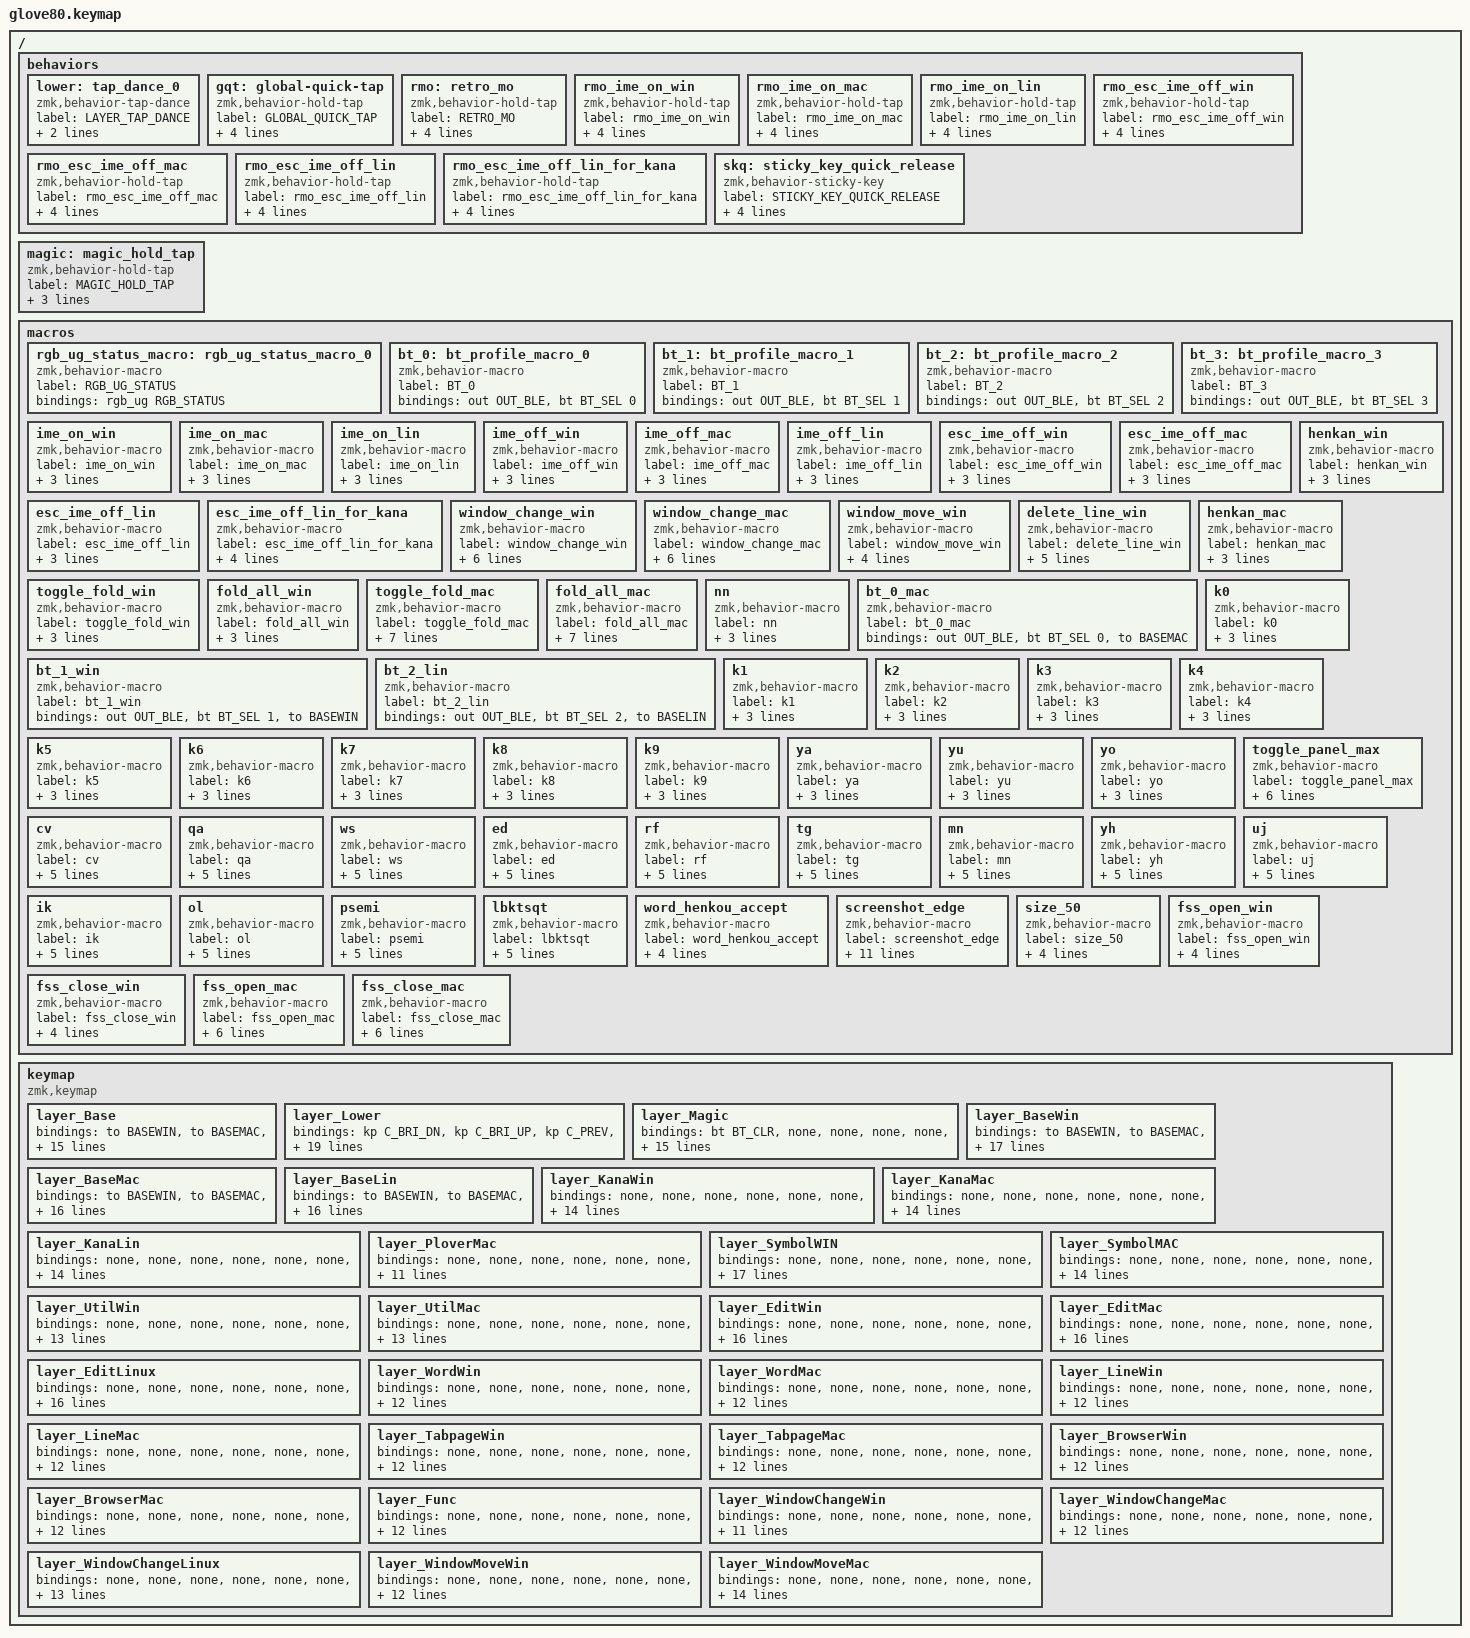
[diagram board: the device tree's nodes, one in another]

/*
 * Copyright (c) 2020 The ZMK Contributors
 * Copyright (c) 2022 Innaworks Development Limited, trading as MoErgo
 *
 * SPDX-License-Identifier: MIT
 */


/* THIS FILE WAS GENERATED BY GLOVE80 LAYOUT EDITOR
 *
 * This file was generated automatically. You may or may not want to
 * edit it directly.
 */

#include <behaviors.dtsi>
/* Include all behaviour includes needed by system behaviors/macros */
#include <dt-bindings/zmk/outputs.h>

/* Include behaviour includes needed by key binds - automatically generated */
#include <dt-bindings/zmk/keys.h>
#include <dt-bindings/zmk/bt.h>
#include <dt-bindings/zmk/rgb.h>
#include <dt-bindings/zmk/outputs.h>


// レイヤーはmaxで32個の模様。それ以上にするとビルドはできるが、動作しない。
#define ORIGINAL_BASE 0
#define ORIGINAL_LOWER 1
#define ORIGINAL_MAGIC 2
#define BASEWIN 3
#define BASEMAC 4
#define BASELIN 5
#define KANAWIN 6
#define KANAMAC 7
#define KANALIN 8
#define PLOVERMAC 9
#define SYMBOLWIN 10
#define SYMBOLMAC 11
#define UTILWIN  12
#define UTILMAC 13
#define EDITWIN 14
#define EDITMAC 15
#define EDITLIN 16
#define WORDWIN 17
#define WORDMAC 18
#define LINEWIN 19
#define LINEMAC 20
#define TABPAGEWIN 21
#define TABPAGEMAC 22
#define BROWSERWIN 23
#define BROWSERMAC 24
#define FUNC 25
#define WINDOWCHANGEWIN 26
#define WINDOWCHANGEMAC 27
#define WINDOWCHANGELIN 28
#define WINDOWMOVEWIN 29
#define WINDOWMOVEMAC 30


/ {
    /* Glove80 system behavior & macros */
    behaviors {
        // For the "layer" key, it'd nice to be able to use it as either a shift or a toggle.
        // Configure it as a tap dance, so the first tap (or hold) is a &mo and the second tap is a &to
        lower: tap_dance_0 {
            compatible = "zmk,behavior-tap-dance";
            label = "LAYER_TAP_DANCE";
            #binding-cells = <0>;
            tapping-term-ms = <200>;
            bindings = <&mo ORIGINAL_LOWER>, <&to ORIGINAL_LOWER>;
        };
        gqt: global-quick-tap {
            compatible = "zmk,behavior-hold-tap";
            label = "GLOBAL_QUICK_TAP";
            #binding-cells = <2>;
            flavor = "hold-preferred";
            tapping-term-ms = <200>;
            retro-tap;
            bindings = <&kp>, <&kp>;
        };
        rmo: retro_mo {
            compatible = "zmk,behavior-hold-tap";
            label = "RETRO_MO";
            #binding-cells = <2>;
            flavor = "hold-preferred";
            tapping-term-ms = <200>;
            retro-tap;
            bindings = <&mo>, <&kp>;
        };
        rmo_ime_on_win: rmo_ime_on_win {
            compatible = "zmk,behavior-hold-tap";
            label = "rmo_ime_on_win";
            #binding-cells = <2>;
            flavor = "hold-preferred";
            tapping-term-ms = <0>;
            retro-tap;
            bindings = <&mo>, <&ime_on_win>;
        };
        rmo_ime_on_mac: rmo_ime_on_mac {
            compatible = "zmk,behavior-hold-tap";
            label = "rmo_ime_on_mac";
            #binding-cells = <2>;
            flavor = "hold-preferred";
            tapping-term-ms = <0>;
            retro-tap;
            bindings = <&mo>, <&ime_on_mac>;
        };
        rmo_ime_on_lin: rmo_ime_on_lin {
            compatible = "zmk,behavior-hold-tap";
            label = "rmo_ime_on_lin";
            #binding-cells = <2>;
            flavor = "hold-preferred";
            tapping-term-ms = <0>;
            retro-tap;
            bindings = <&mo>, <&ime_on_lin>;
        };
        rmo_esc_ime_off_win: rmo_esc_ime_off_win {
            compatible = "zmk,behavior-hold-tap";
            label = "rmo_esc_ime_off_win";
            #binding-cells = <2>;
            flavor = "hold-preferred";
            tapping-term-ms = <0>;
            retro-tap;
            bindings = <&mo>, <&esc_ime_off_win>;
        };
        rmo_esc_ime_off_mac: rmo_esc_ime_off_mac {
            compatible = "zmk,behavior-hold-tap";
            label = "rmo_esc_ime_off_mac";
            #binding-cells = <2>;
            flavor = "hold-preferred";
            tapping-term-ms = <0>;
            retro-tap;
            bindings = <&mo>, <&esc_ime_off_mac>;
        };
        rmo_esc_ime_off_lin: rmo_esc_ime_off_lin {
            compatible = "zmk,behavior-hold-tap";
            label = "rmo_esc_ime_off_lin";
            #binding-cells = <2>;
            flavor = "hold-preferred";
            tapping-term-ms = <0>;
            retro-tap;
            bindings = <&mo>, <&esc_ime_off_lin>;
        };
        rmo_esc_ime_off_lin_for_kana: rmo_esc_ime_off_lin_for_kana {
            compatible = "zmk,behavior-hold-tap";
            label = "rmo_esc_ime_off_lin_for_kana";
            #binding-cells = <2>;
            flavor = "hold-preferred";
            tapping-term-ms = <0>;
            retro-tap;
            bindings = <&mo>, <&esc_ime_off_lin_for_kana>;
        };
        skq: sticky_key_quick_release {
            compatible = "zmk,behavior-sticky-key";
            label = "STICKY_KEY_QUICK_RELEASE";
            #binding-cells = <1>;
            bindings = <&kp>;
            release-after-ms = <1000>;
            quick-release;
            ignore-modifiers;
        };
    };

    magic: magic_hold_tap {
        compatible = "zmk,behavior-hold-tap";
        label = "MAGIC_HOLD_TAP";
        #binding-cells = <2>;
        flavor = "tap-preferred";
        tapping-term-ms = <200>;
        bindings = <&mo>, <&rgb_ug_status_macro>;
    };

    macros {
        rgb_ug_status_macro: rgb_ug_status_macro_0 {
            label = "RGB_UG_STATUS";
            compatible = "zmk,behavior-macro";
            #binding-cells = <0>;
            bindings
                = <&rgb_ug RGB_STATUS>;
        };

        bt_0: bt_profile_macro_0 {
            label = "BT_0";
            compatible = "zmk,behavior-macro";
            #binding-cells = <0>;
            bindings
                = <&out OUT_BLE>,
                  <&bt BT_SEL 0>;
        };

        bt_1: bt_profile_macro_1 {
            label = "BT_1";
            compatible = "zmk,behavior-macro";
            #binding-cells = <0>;
            bindings
                = <&out OUT_BLE>,
                  <&bt BT_SEL 1>;
        };

        bt_2: bt_profile_macro_2 {
            label = "BT_2";
            compatible = "zmk,behavior-macro";
            #binding-cells = <0>;
            bindings
                = <&out OUT_BLE>,
                  <&bt BT_SEL 2>;
        };

        bt_3: bt_profile_macro_3 {
            label = "BT_3";
            compatible = "zmk,behavior-macro";
            #binding-cells = <0>;
            bindings
                = <&out OUT_BLE>,
                  <&bt BT_SEL 3>;
        };

        ime_on_win: ime_on_win {
            label = "ime_on_win";
            compatible = "zmk,behavior-macro";
            #binding-cells = <0>;
            wait-ms = <0>;
            tap-ms = <0>;
            bindings
                = <&kp LANG1>
                , <&to KANAWIN>
                ;
        };
        ime_on_mac: ime_on_mac {
            label = "ime_on_mac";
            compatible = "zmk,behavior-macro";
            #binding-cells = <0>;
            wait-ms = <0>;            
            tap-ms = <0>;
            bindings
                = <&kp LANG1>
                , <&to KANAMAC>
                ;
        };
        ime_on_lin: ime_on_lin {
            label = "ime_on_lin";
            compatible = "zmk,behavior-macro";
            #binding-cells = <0>;
            wait-ms = <0>;            
            tap-ms = <0>;
            bindings
                = <&kp LANG1>
                , <&to KANALIN>
                ;
        };
        ime_off_win: ime_off_win {
            label = "ime_off_win";
            compatible = "zmk,behavior-macro";
            #binding-cells = <0>;
            wait-ms = <0>;            
            tap-ms = <0>;
            bindings
                = <&kp LANG2>
                , <&to BASEWIN>
                ;
        };
        ime_off_mac: ime_off_mac {
            label = "ime_off_mac";
            compatible = "zmk,behavior-macro";
            #binding-cells = <0>;
            wait-ms = <0>;            
            tap-ms = <0>;
            bindings
                = <&kp LANG2>
                , <&to BASEMAC>
                ;
        };
        ime_off_lin: ime_off_lin {
            label = "ime_off_lin";
            compatible = "zmk,behavior-macro";
            #binding-cells = <0>;
            wait-ms = <0>;            
            tap-ms = <0>;
            bindings
                = <&kp LANG2>
                , <&to BASELIN>
                ;
        };
        esc_ime_off_win: esc_ime_off_win {
            label = "esc_ime_off_win";
            compatible = "zmk,behavior-macro";
            #binding-cells = <0>;
            wait-ms = <0>;            
            tap-ms = <0>;
            bindings
                = <&kp LANG2>
                , <&kp ESC>
                , <&to BASEWIN>
                ;
        };
        esc_ime_off_mac: esc_ime_off_mac {
            label = "esc_ime_off_mac";
            compatible = "zmk,behavior-macro";
            #binding-cells = <0>;
            wait-ms = <0>;            
            tap-ms = <0>;
            bindings
                = <&kp LANG2>
                , <&kp ESC>
                , <&to BASEMAC>
                ;
        };
        esc_ime_off_lin: esc_ime_off_lin {
            label = "esc_ime_off_lin";
            compatible = "zmk,behavior-macro";
            #binding-cells = <0>;
            wait-ms = <0>;            
            tap-ms = <0>;
            bindings
                = <&kp LANG2>
                , <&kp ESC>
                , <&to BASELIN>
                ;
        };
        esc_ime_off_lin_for_kana: esc_ime_off_lin_for_kana {
            label = "esc_ime_off_lin_for_kana";
            compatible = "zmk,behavior-macro";
            #binding-cells = <0>;
            wait-ms = <0>;            
            tap-ms = <0>;
            bindings
                = <&kp LANG2>
                , <&kp A>
                , <&kp BSPC>
                , <&kp ESC>
                , <&to BASELIN>
                ;
        };
        window_change_win: window_change_win {
            label = "window_change_win";
            compatible = "zmk,behavior-macro";
            #binding-cells = <0>;
            wait-ms = <0>;            
            tap-ms = <0>;
            bindings
                = <&macro_press &kp LALT &mo WINDOWCHANGEWIN>
                , <&macro_tap &kp TAB>
                , <&macro_pause_for_release>
                , <&macro_release &kp LALT &mo WINDOWCHANGEWIN>
                ;
        };
        window_change_mac: window_change_mac {
            label = "window_change_mac";
            compatible = "zmk,behavior-macro";
            #binding-cells = <0>;
            wait-ms = <0>;            
            tap-ms = <0>;
            bindings
                = <&macro_press &kp LGUI &mo WINDOWCHANGEMAC>
                , <&macro_tap &kp TAB>
                , <&macro_pause_for_release>
                , <&macro_release &kp LGUI &mo WINDOWCHANGEMAC>
                ;
        };
        window_move_win: window_move_win {
            label = "window_move_win";
            compatible = "zmk,behavior-macro";
            #binding-cells = <0>;
            wait-ms = <0>;            
            tap-ms = <0>;
            bindings
                = <&macro_tap &kp LA(LS(B))>
                , <&mo WINDOWMOVEWIN>
                ;
        };
        delete_line_win: delete_line_win {
            label = "delete_line_win";
            compatible = "zmk,behavior-macro";
            #binding-cells = <0>;
            wait-ms = <0>;            
            tap-ms = <0>;
            bindings
                = <&macro_press &kp LSHFT>
                , <&macro_tap &kp HOME>
                , <&macro_tap &kp BSPC>
                , <&macro_release &kp LSHFT>
                ;
        };
        henkan_win: henkan_win {
            label = "henkan_win";
            compatible = "zmk,behavior-macro";
            #binding-cells = <0>;
            wait-ms = <0>;            
            tap-ms = <0>;
            bindings
                = < &kp INT4>
                , < &to KANAWIN>
                ;
        };
        henkan_mac: henkan_mac {
            label = "henkan_mac";
            compatible = "zmk,behavior-macro";
            #binding-cells = <0>;
            wait-ms = <0>;            
            tap-ms = <0>;
            bindings
                = < &kp LANG1>
                , < &kp LANG1>
                , < &to KANAMAC>
                ;
        };
        toggle_fold_win: toggle_fold_win {
            label = "toggle_fold_win";
            compatible = "zmk,behavior-macro";
            #binding-cells = <0>;
            wait-ms = <0>;            
            tap-ms = <0>;
            bindings
                = < &kp LC(K)>
                , < &kp LC(L)>
                ;
        };
        fold_all_win: fold_all_win {
            label = "fold_all_win";
            compatible = "zmk,behavior-macro";
            #binding-cells = <0>;
            wait-ms = <0>;            
            tap-ms = <0>;
            bindings
                = < &kp LC(K)>
                , < &kp LC(N0)>
                ;
        };
        toggle_fold_mac: toggle_fold_mac {
            label = "toggle_fold_mac";
            compatible = "zmk,behavior-macro";
            #binding-cells = <0>;
            wait-ms = <0>;            
            tap-ms = <0>;
            bindings
                = <&macro_press &kp LGUI>
                , <&macro_press &kp K>
                , <&macro_release &kp K>
                , <&macro_release &kp LGUI>
                , <&macro_wait_time 200>
                , <&macro_press &kp LGUI>
                , <&macro_press &kp L>
                , <&macro_release &kp L>
                , <&macro_release &kp LGUI>
                ;
        };
        fold_all_mac: fold_all_mac {
            label = "fold_all_mac";
            compatible = "zmk,behavior-macro";
            #binding-cells = <0>;
            wait-ms = <0>;            
            tap-ms = <0>;
            bindings
                = <&macro_press &kp LGUI>
                , <&macro_press &kp K>
                , <&macro_release &kp K>
                , <&macro_release &kp LGUI>
                , <&macro_wait_time 200>
                , <&macro_press &kp LGUI>
                , <&macro_press &kp N0>
                , <&macro_release &kp N0>
                , <&macro_release &kp LGUI>
                ;
        };
        nn: nn {
            label = "nn";
            compatible = "zmk,behavior-macro";
            #binding-cells = <0>;
            wait-ms = <0>;            
            tap-ms = <0>;
            bindings
                = <&macro_tap_time 0>
                , < &kp N>
                , < &kp N>
                ;
        };
        bt_0_mac: bt_0_mac {
            label = "bt_0_mac";
            compatible = "zmk,behavior-macro";
            #binding-cells = <0>;
            bindings
                = <&out OUT_BLE>
                , <&bt BT_SEL 0>
                , <&to BASEMAC>
                ;
        };
        bt_1_win: bt_1_win {
            label = "bt_1_win";
            compatible = "zmk,behavior-macro";
            #binding-cells = <0>;
            bindings
                = <&out OUT_BLE>
                , <&bt BT_SEL 1>
                , <&to BASEWIN>
                ;
        };
        bt_2_lin: bt_2_lin {
            label = "bt_2_lin";
            compatible = "zmk,behavior-macro";
            #binding-cells = <0>;
            bindings
                = <&out OUT_BLE>
                , <&bt BT_SEL 2>
                , <&to BASELIN> 
                ;
        };
        k0: k0 {
            label = "k0";
            compatible = "zmk,behavior-macro";
            #binding-cells = <0>;
            wait-ms = <0>;            
            tap-ms = <0>;
            bindings
                = < &kp LANG2>
                , < &kp N0>
                , < &kp LANG1>
                ;
        };
        k1: k1 {
            label = "k1";
            compatible = "zmk,behavior-macro";
            #binding-cells = <0>;
            wait-ms = <0>;            
            tap-ms = <0>;
            bindings
                = < &kp LANG2>
                , < &kp N1>
                , < &kp LANG1>
                ;
        };
        k2: k2 {
            label = "k2";
            compatible = "zmk,behavior-macro";
            #binding-cells = <0>;
            wait-ms = <0>;            
            tap-ms = <0>;
            bindings
                = < &kp LANG2>
                , < &kp N2>
                , < &kp LANG1>
                ;
        };
        k3: k3 {
            label = "k3";
            compatible = "zmk,behavior-macro";
            #binding-cells = <0>;
            wait-ms = <0>;            
            tap-ms = <0>;
            bindings
                = < &kp LANG2>
                , < &kp N3>
                , < &kp LANG1>
                ;
        };
        k4: k4 {
            label = "k4";
            compatible = "zmk,behavior-macro";
            #binding-cells = <0>;
            wait-ms = <0>;            
            tap-ms = <0>;
            bindings
                = < &kp LANG2>
                , < &kp N4>
                , < &kp LANG1>
                ;
        };
        k5: k5 {
            label = "k5";
            compatible = "zmk,behavior-macro";
            #binding-cells = <0>;
            wait-ms = <0>;            
            tap-ms = <0>;
            bindings
                = < &kp LANG2>
                , < &kp N5>
                , < &kp LANG1>
                ;
        };
        k6: k6 {
            label = "k6";
            compatible = "zmk,behavior-macro";
            #binding-cells = <0>;
            wait-ms = <0>;            
            tap-ms = <0>;
            bindings
                = < &kp LANG2>
                , < &kp N6>
                , < &kp LANG1>
                ;
        };
        k7: k7 {
            label = "k7";
            compatible = "zmk,behavior-macro";
            #binding-cells = <0>;
            wait-ms = <0>;            
            tap-ms = <0>;
            bindings
                = < &kp LANG2>
                , < &kp N7>
                , < &kp LANG1>
                ;
        };
        k8: k8 {
            label = "k8";
            compatible = "zmk,behavior-macro";
            #binding-cells = <0>;
            wait-ms = <0>;            
            tap-ms = <0>;
            bindings
                = < &kp LANG2>
                , < &kp N8>
                , < &kp LANG1>
                ;
        };
        k9: k9 {
            label = "k9";
            compatible = "zmk,behavior-macro";
            #binding-cells = <0>;
            wait-ms = <0>;            
            tap-ms = <0>;
            bindings
                = < &kp LANG2>
                , < &kp N9>
                , < &kp LANG1>
                ;
        };
        ya: ya {
            label = "ya";
            compatible = "zmk,behavior-macro";
            #binding-cells = <0>;
            wait-ms = <0>;            
            tap-ms = <0>;
            bindings
                = < &kp Y>
                , < &kp A>
                ;
        };
        yu: yu {
            label = "yu";
            compatible = "zmk,behavior-macro";
            #binding-cells = <0>;
            wait-ms = <0>;            
            tap-ms = <0>;
            bindings
                = < &kp Y>
                , < &kp U>
                ;
        };
        yo: yo {
            label = "yo";
            compatible = "zmk,behavior-macro";
            #binding-cells = <0>;
            wait-ms = <0>;            
            tap-ms = <0>;
            bindings
                = < &kp Y>
                , < &kp O>
                ;
        };
        toggle_panel_max: toggle_panel_max {
            label = "toggle_panel_max";
            compatible = "zmk,behavior-macro";
            #binding-cells = <0>;
            wait-ms = <0>;            
            tap-ms = <0>;
            bindings
                = <&macro_press &kp LGUI>
                , <&macro_press &kp K>
                , <&macro_release &kp K>
                , <&macro_release &kp LGUI>
                , <&macro_wait_time 200>
                , <&macro_press &kp M>
                , <&macro_release &kp M>
                ;
        };
        cv: cv {
            label = "cv";
            compatible = "zmk,behavior-macro";
            #binding-cells = <0>;
            wait-ms = <0>;            
            tap-ms = <0>;
            bindings
                = <&macro_press &kp C &kp V>
                , <&macro_pause_for_release>
                , <&macro_release &kp C &kp V>
                ;
        };
        qa: qa {
            label = "qa";
            compatible = "zmk,behavior-macro";
            #binding-cells = <0>;
            wait-ms = <0>;            
            tap-ms = <0>;
            bindings
                = <&macro_press &kp Q &kp A>
                , <&macro_pause_for_release>
                , <&macro_release &kp Q &kp A>
                ;
        };
        ws: ws {
            label = "ws";
            compatible = "zmk,behavior-macro";
            #binding-cells = <0>;
            wait-ms = <0>;            
            tap-ms = <0>;
            bindings
                = <&macro_press &kp W &kp S>
                , <&macro_pause_for_release>
                , <&macro_release &kp W &kp S>
                ;
        };
        ed: ed {
            label = "ed";
            compatible = "zmk,behavior-macro";
            #binding-cells = <0>;
            wait-ms = <0>;            
            tap-ms = <0>;
            bindings
                = <&macro_press &kp E &kp D>
                , <&macro_pause_for_release>
                , <&macro_release &kp E &kp D>
                ;
        };
        rf: rf {
            label = "rf";
            compatible = "zmk,behavior-macro";
            #binding-cells = <0>;
            wait-ms = <0>;            
            tap-ms = <0>;
            bindings
                = <&macro_press &kp R &kp F>
                , <&macro_pause_for_release>
                , <&macro_release &kp R &kp F>
                ;
        };
        tg: tg {
            label = "tg";
            compatible = "zmk,behavior-macro";
            #binding-cells = <0>;
            wait-ms = <0>;            
            tap-ms = <0>;
            bindings
                = <&macro_press &kp T &kp G>
                , <&macro_pause_for_release>
                , <&macro_release &kp T &kp G>
                ;
        };
        mn: mn {
            label = "mn";
            compatible = "zmk,behavior-macro";
            #binding-cells = <0>;
            wait-ms = <0>;            
            tap-ms = <0>;
            bindings
                = <&macro_press &kp M &kp N>
                , <&macro_pause_for_release>
                , <&macro_release &kp M &kp N>
                ;
        };
        yh: yh {
            label = "yh";
            compatible = "zmk,behavior-macro";
            #binding-cells = <0>;
            wait-ms = <0>;            
            tap-ms = <0>;
            bindings
                = <&macro_press &kp Y &kp H>
                , <&macro_pause_for_release>
                , <&macro_release &kp Y &kp H>
                ;
        };
        uj: uj {
            label = "uj";
            compatible = "zmk,behavior-macro";
            #binding-cells = <0>;
            wait-ms = <0>;            
            tap-ms = <0>;
            bindings
                = <&macro_press &kp U &kp J>
                , <&macro_pause_for_release>
                , <&macro_release &kp U &kp J>
                ;
        };
        ik: ik {
            label = "ik";
            compatible = "zmk,behavior-macro";
            #binding-cells = <0>;
            wait-ms = <0>;            
            tap-ms = <0>;
            bindings
                = <&macro_press &kp I &kp K>
                , <&macro_pause_for_release>
                , <&macro_release &kp I &kp K>
                ;
        };
        ol: ol {
            label = "ol";
            compatible = "zmk,behavior-macro";
            #binding-cells = <0>;
            wait-ms = <0>;            
            tap-ms = <0>;
            bindings
                = <&macro_press &kp O &kp L>
                , <&macro_pause_for_release>
                , <&macro_release &kp O &kp L>
                ;
        };
        psemi: psemi {
            label = "psemi";
            compatible = "zmk,behavior-macro";
            #binding-cells = <0>;
            wait-ms = <0>;            
            tap-ms = <0>;
            bindings
                = <&macro_press &kp P &kp SEMI>
                , <&macro_pause_for_release>
                , <&macro_release &kp P &kp SEMI>
                ;
        };
        lbktsqt: lbktsqt {
            label = "lbktsqt";
            compatible = "zmk,behavior-macro";
            #binding-cells = <0>;
            wait-ms = <0>;            
            tap-ms = <0>;
            bindings
                = <&macro_press &kp LBKT &kp SQT>
                , <&macro_pause_for_release>
                , <&macro_release &kp LBKT &kp SQT>
                ;
        };
        word_henkou_accept: word_henkou_accept {
            label = "word_henkou_accept";
            compatible = "zmk,behavior-macro";
            #binding-cells = <0>;
            wait-ms = <0>;            
            tap-ms = <0>;
            bindings
                = < &kp LALT>
                , < &kp R>
                , < &kp Z>
                , < &kp T>
                , < &kp A>
                , < &kp N2>
                , < &kp M>
                ;
        };
        screenshot_edge: screenshot_edge {
            label = "screenshot_edge";
            compatible = "zmk,behavior-macro";
            #binding-cells = <0>;
            wait-ms = <200>;            
            tap-ms = <0>;
            bindings
                = < &kp LC(LS(S))>
                , < &kp TAB>
                , < &kp TAB>
                , < &kp TAB>
                , < &kp RET>
                , <&macro_pause_for_release>
                , < &kp TAB>
                , <&macro_wait_time 200>
                , < &kp TAB>
                , <&macro_wait_time 200>
                , < &kp TAB>
                , <&macro_wait_time 200>
                , < &kp TAB>
                , <&macro_wait_time 200>
                , < &kp TAB>
                , <&macro_wait_time 200>
                , < &kp TAB>
                , <&macro_wait_time 200>
                , < &kp TAB>
                , <&macro_wait_time 200>
                , < &kp RET>
                ;
        };
        size_50: size_50 {
            label = "size_50";
            compatible = "zmk,behavior-macro";
            #binding-cells = <0>;
            wait-ms = <100>;            
            tap-ms = <0>;
            bindings
                = < &kp LALT>
                , < &kp J>
                , < &kp P>
                , < &kp S>
                , < &kp Z>
                , < &kp LS(LC(RIGHT))>
                , < &kp N5>
                , < &kp N0>
                , < &kp RET>
                ;
        };
        fss_open_win: fss_open_win {
            label = "fss_open_win";
            compatible = "zmk,behavior-macro";
            #binding-cells = <0>;
            wait-ms = <10>;            
            tap-ms = <0>;
            bindings
                = <&kp INT1>
                , <&kp F>
                , <&kp LS(COMMA)>
                , <&kp LS(COMMA)>
                , <&kp SPACE>
                , <&kp BSPC>
                ;
        };
        fss_close_win: fss_close_win {
            label = "fss_close_win";
            compatible = "zmk,behavior-macro";
            #binding-cells = <0>;
            wait-ms = <10>;            
            tap-ms = <0>;
            bindings
                = <&kp INT1>
                , <&kp F>
                , <&kp LS(DOT)>
                , <&kp LS(DOT)>
                , <&kp SPACE>
                , <&kp BSPC>
                ;
        };
        fss_open_mac: fss_open_mac {
            label = "fss_open_mac";
            compatible = "zmk,behavior-macro";
            #binding-cells = <0>;
            wait-ms = <0>;            
            tap-ms = <0>;
            bindings
                = <&kp BSLH>
                , <&kp F>
                , <&macro_press &kp LSHIFT>
                , <&macro_tap &kp COMMA>
                , <&macro_tap &kp COMMA>
                , <&macro_release  &kp LSHIFT>
                , <&macro_tap &kp SPACE>
                , <&macro_tap &kp BSPC>
                ;
        };
        fss_close_mac: fss_close_mac {
            label = "fss_close_mac";
            compatible = "zmk,behavior-macro";
            #binding-cells = <0>;
            wait-ms = <0>;            
            tap-ms = <0>;
            bindings
                = <&kp BSLH>
                , <&kp F>
                , <&macro_press &kp LSHIFT>
                , <&macro_tap &kp DOT>
                , <&macro_tap &kp DOT>
                , <&macro_release  &kp LSHIFT>
                , <&macro_tap &kp SPACE>
                , <&macro_tap &kp BSPC>
                ;
        };
    };

    /* Automatically generated keymap */
    keymap {
        compatible = "zmk,keymap";

        
        layer_Base {
            bindings = <
                        &to BASEWIN &to BASEMAC &to ORIGINAL_BASE &to BASELIN &kp F5                                                                                  &kp F6 &kp F7    &kp F8   &kp F9   &kp F10
                        &kp EQUAL   &kp N1      &kp N2            &kp N3      &kp N4    &kp N5                                                           &kp LS(LALT) &kp N7 &kp N8    &kp N9   &kp N0   &kp MINUS
                        &kp TAB     &kp Q       &kp W             &kp E       &kp R     &kp T                                                            &kp Y        &kp U  &kp I     &kp O    &kp P    &kp BSLH
                        &kp ESC     &kp A       &kp S             &kp D       &kp F     &kp G                                                            &kp H        &kp J  &kp K     &kp L    &kp SEMI &kp SQT
                        &kp GRAVE   &kp Z       &kp X             &kp C       &kp V     &kp B  &kp LSHFT &kp LCTRL &lower   &kp LGUI &kp RCTRL &kp RSHFT &kp N        &kp M  &kp COMMA &kp DOT  &kp FSLH &kp PG_UP
                        &magic 2 0  &kp F1      &kp F2            &kp LEFT    &kp RIGHT        &kp BSPC  &kp DEL   &kp LALT &kp RALT &kp RET   &kp SPACE              &kp UP &kp DOWN  &kp LBKT &kp RBKT &kp PG_DN
            >;
        };

        
        layer_Lower {
            bindings = <
                        &kp C_BRI_DN &kp C_BRI_UP &kp C_PREV     &kp C_NEXT     &kp C_PP                                                                                        &kp C_MUTE &kp C_VOL_DN &kp C_VOL_UP &none           &kp PAUSE_BREAK
                        &none        &none        &none          &none          &none           &kp HOME                                                  &kp LEFT_PARENTHESIS  &kp KP_NUM &kp KP_EQUAL &kp KP_SLASH &kp KP_MULTIPLY &kp PRINTSCREEN
                        &none        &none        &none          &kp UP_ARROW   &kp AT          &kp END                                                   &kp RIGHT_PARENTHESIS &kp KP_N7  &kp KP_N8    &kp KP_N9    &kp KP_MINUS    &kp SCROLLLOCK
                        &none        &none        &kp LEFT_ARROW &kp DOWN_ARROW &kp RIGHT_ARROW &kp PG_UP                                                 &kp PERCENT           &kp KP_N4  &kp KP_N5    &kp KP_N6    &kp KP_PLUS     &none
                        &none        &kp K_APP    &none          &kp F11        &kp F12         &kp PG_DN &none &none &to ORIGINAL_BASE &none &none &none &kp COMMA             &kp KP_N1  &kp KP_N2    &kp KP_N3    &kp KP_ENTER    &none
                        &magic 2 0   &kp CAPS     &kp INS        &kp F11        &kp F12                   &none &none &none             &none &none &none                       &kp KP_N0  &kp KP_N0    &kp KP_DOT   &kp KP_ENTER    &none
            >;
        };

        layer_Magic {
            bindings = <
                        &bt BT_CLR  &none           &none           &none           &none                                                                            &none &none &none &none &bt BT_CLR_ALL
                        &none       &none           &none           &none           &none           &none                                                      &none &none &none &none &none &none
                        &none       &rgb_ug RGB_SPI &rgb_ug RGB_SAI &rgb_ug RGB_HUI &rgb_ug RGB_BRI &rgb_ug RGB_TOG                                            &none &none &none &none &none &none
                        &bootloader &rgb_ug RGB_SPD &rgb_ug RGB_SAD &rgb_ug RGB_HUD &rgb_ug RGB_BRD &rgb_ug RGB_EFF                                            &none &none &none &none &none &bootloader
                        &none       &none           &none           &none           &none           &none           &bt_2 &bt_3 &none        &none &none &none &none &none &none &none &none &none
                        &none       &none           &none           &none           &none                           &bt_0 &bt_1 &out OUT_USB &none &none &none       &none &none &none &none &none
            >;
        };

        
        layer_BaseWin {
            bindings = <
                        &to BASEWIN         &to BASEMAC &to ORIGINAL_BASE &to BASELIN &none                                                                                                                                   &none &none &bt_2_lin    &bt_0_mac &bt_1_win
                        &none               &none       &none             &kp Y       &none &none                                                                                                                       &none &none &kp B &none        &none     &none
                        &none               &none       &kp H             &kp O       &kp U &kp X                                                                                                                       &kp G &kp C &kp M &kp R        &none     &none
                        &word_henkou_accept &kp Y       &kp I             &kp E       &kp A &kp DOT                                                                                                                     &kp D &kp S &kp T &kp N        &kp B     &none
                        &none               &none       &kp LS(N2)        &kp EXCL    &kp K &kp COMMA &sk LCTRL         &sk LCTRL                 &sk LSHFT &skq RALT  &skq RGUI                      &skq RCTRL         &kp W &kp F &kp L &kp P        &none     &none
                        &magic 2 0          &none       &kp LS(N7)        &kp Q       &kp J           &gqt LSHFT SPACE &rmo_ime_on_win EDITWIN 0 &skq LALT &skq RSHFT &rmo_esc_ime_off_win UTILWIN 0 &rmo SYMBOLWIN RET       &kp V &kp Z &kp LS(FSLH) &none     &none
            >;
        };

        
        layer_BaseMac {
            bindings = <
                        &to BASEWIN &to BASEMAC &to ORIGINAL_BASE &to BASELIN &none                                                                                                                                      &none &none &bt_2_lin    &bt_0_mac &bt_1_win
                        &none       &none       &none             &kp Y       &none &none                                                                                                                          &none &none &kp B &none        &none     &none
                        &none       &none       &kp H             &kp O       &kp U &kp X                                                                                                                          &kp G &kp C &kp M &kp R        &none     &none
                        &none       &kp Y       &kp I             &kp E       &kp A &kp DOT                                                                                                                        &kp D &kp S &kp T &kp N        &kp B     &none
                        &none       &none       &kp DQT           &kp EXCL    &kp K &kp COMMA &sk LGUI         &sk LCTRL                 &kp LSHFT &skq RALT     &skq RCTRL                     &kp LG(LS(I))      &kp W &kp F &kp L &kp P        &none     &none
                        &magic 2 0  &none       &kp SQT           &kp Q       &kp J           &gqt LSHFT SPACE &rmo_ime_on_mac EDITMAC 0 &skq LALT &to PLOVERMAC &rmo_esc_ime_off_mac UTILMAC 0 &rmo SYMBOLMAC RET       &kp V &kp Z &kp LS(FSLH) &none     &none
            >;
        };

        layer_BaseLin {
            bindings = <
                        &to BASEWIN &to BASEMAC &to ORIGINAL_BASE &to BASELIN &none                                                                                                                                  &none &none &bt_2_lin    &bt_0_mac &bt_1_win
                        &none       &none       &none             &kp Y       &none &none                                                                                                                      &none &none &kp B &none        &none     &none
                        &none       &none       &kp H             &kp O       &kp U &kp X                                                                                                                      &kp G &kp C &kp M &kp R        &none     &none
                        &none       &kp Y       &kp I             &kp E       &kp A &kp DOT                                                                                                                    &kp D &kp S &kp T &kp N        &kp B     &none
                        &none       &none       &kp DQT           &kp EXCL    &kp K &kp COMMA &sk LCTRL         &sk LCTRL                 &kp LSHFT &skq RALT &skq RGUI                     &skq RCTRL          &kp W &kp F &kp L &kp P        &none     &none
                        &magic 2 0  &none       &kp SQT           &kp Q       &kp J           &gqt LSHFT SPACE &rmo_ime_on_lin EDITLIN 0 &skq LALT &skq RSHFT     &rmo_esc_ime_off_lin UTILWIN 0 &rmo SYMBOLMAC RET       &kp V &kp Z &kp LS(FSLH) &none     &none
            >;
        };
        
        layer_KanaWin {
            bindings = <
                        &none &none &none &none &none                                                                                                         &none &none &bt_2_lin &bt_0_mac &bt_1_win
                        &none &none &none &kp H &none &none                                                                                         &none     &none &none &none     &none     &none
                        &none &none &kp M &kp R &kp S &kp H                                                                                         &kp Y     &kp E &kp O &kp MINUS &none     &none
                        &none &kp X &kp K &kp T &kp N &kp D                                                                                         &kp DOT   &kp A &kp I &kp U     &kp V     &none
                        &none &none &kp B &kp W &nn   &kp G &sk LCTRL &sk LCTRL   &sk LGUI  &none &none                          &kp Z              &kp COMMA &yo   &yu   &ya       &none     &none
                        &none &none &kp P &kp F &kp Z       &kp SPACE &mo EDITWIN &skq LALT &none &rmo_esc_ime_off_win UTILWIN 0 &rmo SYMBOLWIN RET           &none &none &none     &none     &none
            >;
        };

        
        layer_KanaMac {
            bindings = <
                        &none &none &none &none &none                                                                                                         &none &none &bt_2_lin &bt_0_mac &bt_1_win
                        &none &none &none &kp H &none &none                                                                                         &none     &none &none &none     &none     &none
                        &none &none &kp M &kp R &kp S &kp H                                                                                         &kp Y     &kp E &kp O &kp MINUS &none     &none
                        &none &kp X &kp K &kp T &kp N &kp D                                                                                         &kp DOT   &kp A &kp I &kp U     &kp V     &none
                        &none &none &kp B &kp W &nn   &kp G &sk LGUI  &sk LCTRL   &none     &none &none                          &kp Z              &kp COMMA &yo   &yu   &ya       &none     &none
                        &none &none &kp P &kp F &kp Z       &kp SPACE &mo EDITMAC &skq LALT &none &rmo_esc_ime_off_mac UTILMAC 0 &rmo SYMBOLMAC RET           &none &none &none     &none     &none
            >;
        };

        layer_KanaLin {
            bindings = <
                        &none &none &none &none &none                                                                                                                  &none &none &bt_2_lin &bt_0_mac &bt_1_win
                        &none &none &none &kp H &none &none                                                                                                  &none     &none &none &none     &none     &none
                        &none &none &kp M &kp R &kp S &kp H                                                                                                  &kp Y     &kp E &kp O &kp MINUS &none     &none
                        &none &kp X &kp K &kp T &kp N &kp D                                                                                                  &kp DOT   &kp A &kp I &kp U     &kp V     &none
                        &none &none &kp B &kp W &nn   &kp G &sk LGUI  &sk LCTRL   &none     &none &none                                   &kp Z              &kp COMMA &yo   &yu   &ya       &none     &none
                        &none &none &kp P &kp F &kp Z       &kp SPACE &mo EDITLIN &skq LALT &none &rmo_esc_ime_off_lin_for_kana UTILWIN 0 &rmo SYMBOLMAC RET           &none &none &none     &none     &none
            >;
        };
        

        layer_PloverMac {
            bindings = <
                        &none &none &none &none &none                                                       &none &none &none &none    &none
                        &none &none &none &none &none &none                                           &none &none &none &none &none    &none
                        &none &kp Q &kp W &kp E &kp R &kp T                                           &kp Y &kp U &kp I &kp O &kp P    &kp LBKT
                        &none &qa   &ws   &ed   &rf   &tg                                             &yh   &uj   &ik   &ol   &psemi   &lbktsqt
                        &none &kp A &kp S &kp D &kp F &kp G &cv   &none &none &none       &none &mn   &kp H &kp J &kp K &kp L &kp SEMI &kp SQT
                        &none &none &none &none &none       &kp C &kp V &none &to BASEMAC &kp N &kp M       &none &none &none &none    &none
            >;
        };
        
        layer_SymbolWIN {
            bindings = <
                        &none &none        &none         &none         &none                                                                   &none         &none         &none               &none        &none
                        &none &none        &none         &kp INT1      &none       &none                                            &none      &none         &kp LS(LBKT)  &none               &none        &none
                        &none &kp LS(N7)   &kp LS(COMMA) &kp LS(MINUS) &kp LS(DOT) &kp LBKT                                         &kp LS(N3) &kp RBKT      &kp LS(INT1)  &kp NON_US_HASH     &kp LS(FSLH) &none
                        &none &kp INT1     &kp LS(N8)    &kp MINUS     &kp LS(N9)  &kp LS(SEMI)                                     &kp LS(N5) &kp LS(RBKT)  &kp SEMI      &kp LS(NON_US_HASH) &kp LS(LBKT) &none
                        &none &kp LA(INT3) &kp LS(SQT)   &kp SQT       &kp FSLH    &kp LS(N4)   &none &none &none &none &none &none &kp EQUAL  &kp LS(INT3)  &kp LS(EQUAL) &kp LS(N6)          &none        &none
                        &none &none        &none         &none         &none                    &none &none &none &none &none &none            &fss_open_win &none         &fss_close_win      &none        &none
            >;
        };

        layer_SymbolMAC {
            bindings = <
                        &none &none    &none         &none     &none                                                                  &none         &none     &none          &none     &none
                        &none &none    &none         &none     &none       &none                                           &none      &none         &none     &none          &none     &none
                        &none &none    &kp LS(COMMA) &kp EQUAL &kp LS(DOT) &kp LS(N2)                                      &kp LS(N3) &kp LBKT      &kp UNDER &kp RBKT       &none     &none
                        &none &kp BSLH &kp LPAR      &kp MINUS &kp RPAR    &kp KP_PLUS                                     &kp LS(N5) &kp LS(LBKT)  &kp SEMI  &kp LS(RBKT)   &kp GRAVE &none
                        &none &none    &kp STAR      &kp COLON &kp FSLH    &kp DLLR    &none &none &none &none &none &none &kp CARET  &kp PIPE      &kp TILDE &kp AMPS       &none     &none
                        &none &none    &none         &none     &none                   &none &none &none &none &none &none            &fss_open_mac &none     &fss_close_mac &none     &none
            >;
        };

        layer_UtilWin {
            bindings = <
                        &none &none  &none       &none       &none                                                                               &none    &none    &none     &none  &none
                        &none &none  &none       &kp N3      &none          &none                                                       &none    &none    &kp N8   &none     &none  &none
                        &none &none  &kp N2      &kp N1      &kp N0         &kp N4                                                      &kp N7   &kp N6   &kp N5   &kp N9    &none  &none
                        &none &kp N3 &none       &mo WORDWIN &mo FUNC       &kp TAB                                                     &kp LEFT &kp DOWN &kp UP   &kp RIGHT &kp N8 &none
                        &none &none  &henkan_win &mo LINEWIN &mo TABPAGEWIN &none   &kp LCTRL &kp LGUI       &kp LALT &none &none &none &kp DEL  &kp BSPC &kp LGUI &none     &none  &none
                        &none &none  &none       &none       &none                  &kp LSHFT &mo BROWSERWIN &none    &none &none &none          &none    &none    &none     &none  &none
            >;
        };

        layer_UtilMac {
            bindings = <
                        &none &none  &none       &none       &none                                                                               &none    &none         &none     &none  &none
                        &none &none  &none       &kp N3      &none          &none                                                       &none    &none    &kp N8        &none     &none  &none
                        &none &none  &kp N2      &kp N1      &kp N0         &kp N4                                                      &kp N7   &kp N6   &kp N5        &kp N9    &none  &none
                        &none &kp N3 &none       &mo WORDMAC &mo FUNC       &kp TAB                                                     &kp LEFT &kp DOWN &kp UP        &kp RIGHT &kp N8 &none
                        &none &none  &henkan_mac &mo LINEMAC &mo TABPAGEMAC &none   &kp LGUI  &kp LCTRL      &kp LALT &none &none &none &none    &kp BSPC &kp LA(SPACE) &none     &none  &none
                        &none &none  &none       &none       &none                  &kp LSHFT &mo BROWSERMAC &none    &none &none &none          &none    &none         &none     &none  &none
            >;
        };

        layer_EditWin {
            bindings = <
                        &none          &none      &none              &none            &none                                                                           &none            &none          &none &none &none
                        &none          &none      &none              &kp LG(LS(S))    &kp LG(PSCRN)    &none                                                    &none &none            &none          &none &none &none
                        &none          &none      &kp LC(W)          &kp LC(FSLH)     &toggle_fold_win &fold_all_win                                            &none &kp LC(J)        &kp LA(M)      &none &none &none
                        &kp LC(LS(N3)) &kp LA(F4) &window_change_win &kp LC(C)        &kp LC(V)        &kp LC(S)                                                &none &kp LC(LA(DOWN)) &kp LC(LA(UP)) &none &none &none
                        &kp LC(LS(N4)) &none      &window_move_win   &kp LC(Y)        &kp LC(X)        &kp LC(Z)     &none &none &none &none &none        &none &none &none            &none          &none &none &none
                        &none          &none      &size_50           &screenshot_edge &kp LG(V)                      &none &none &none &none &ime_off_win &none       &none            &none          &none &none &none
            >;
        };

            
        layer_EditMac {
            bindings = <
                        &none &none     &none              &none          &none                                                                                            &none            &none             &none &none &none
                        &none &none     &none              &kp LG(LS(N4)) &kp LG(LS(N3))   &none                                                                     &none &none            &none             &none &none &none
                        &none &none     &kp LG(W)          &kp LG(FSLH)   &toggle_fold_mac &fold_all_mac                                                             &none &kp LG(J)        &toggle_panel_max &none &none &none
                        &none &kp LG(Q) &window_change_mac &kp LG(C)      &kp LG(V)        &kp LG(S)                                                                 &none &kp LG(LA(DOWN)) &kp LG(LA(UP))    &none &none &none
                        &none &none     &mo WINDOWMOVEMAC  &kp LG(Y)      &kp LG(X)        &kp LG(Z)     &none &none &none &kp LC(LG(E)) &kp LC(LG(C)) &kp LC(LG(A)) &none &none            &none             &none &none &none
                        &none &none     &none              &none          &kp LG(LS(V))                  &none &none &none &none         &ime_off_mac  &none               &none            &none             &none &none &none
            >;
        };

        layer_EditLinux {
            bindings = <
                        &none &none         &none               &none        &none                                                                                                 &none            &none             &none &none &none
                        &none &none         &none               &none        &none             &none                                                                         &none &none            &none             &none &none &none
                        &none &none         &kp LC(W)           &kp LG(FSLH) &kp LG(LC(LS(F))) &kp LG(LC(LS(A)))                                                             &none &kp LG(J)        &kp LG(LC(LS(M))) &none &none &none
                        &none &kp LA(LS(C)) &mo WINDOWCHANGELIN &kp LC(C)    &kp LC(V)         &kp LC(S)                                                                     &none &kp LG(LA(DOWN)) &kp LG(LA(UP))    &none &none &none
                        &none &none         &kp LG(LC(LS(B)))   &kp LC(Y)    &kp LC(X)         &kp LC(Z)         &none &none &none &kp LC(LG(E)) &kp LC(LG(C)) &kp LC(LG(A)) &none &none            &none             &none &none &none
                        &none &none         &none               &none        &kp LG(LS(V))                       &none &none &none &none         &ime_off_lin  &none               &none            &none             &none &none &none
            >;
        };
        
        layer_WordWin {
            bindings = <
                        &none &none &none &none &none                                                            &none        &none     &none         &none &none
                        &none &none &none &none &none &none                                         &none        &none        &none     &none         &none &none
                        &none &none &none &none &none &none                                         &none        &none        &none     &none         &none &none
                        &none &none &none &none &none &none                                         &kp LC(LEFT) &kp PG_DN    &kp PG_UP &kp LC(RIGHT) &none &none
                        &none &none &none &none &none &none &none     &none &none &none &none &none &none        &kp LC(BSPC) &none     &none         &none &none
                        &none &none &none &none &none       &kp LSHFT &none &none &none &none &none              &none        &none     &none         &none &none
            >;
        };

        
        layer_WordMac {
            bindings = <
                        &none &none &none &none &none                                                            &none        &none     &none         &none &none
                        &none &none &none &none &none &none                                         &none        &none        &none     &none         &none &none
                        &none &none &none &none &none &none                                         &none        &none        &none     &none         &none &none
                        &none &none &none &none &none &none                                         &kp LA(LEFT) &kp PG_DN    &kp PG_UP &kp LA(RIGHT) &none &none
                        &none &none &none &none &none &none &none     &none &none &none &none &none &none        &kp LA(BSPC) &none     &none         &none &none
                        &none &none &none &none &none       &kp LSHFT &none &none &none &none &none              &none        &none     &none         &none &none
            >;
        };

        
        layer_LineWin {
            bindings = <
                        &none &none &none &none &none                                                        &none            &none        &none   &none &none
                        &none &none &none &none &none &none                                         &none    &none            &none        &none   &none &none
                        &none &none &none &none &none &none                                         &none    &none            &none        &none   &none &none
                        &none &none &none &none &none &none                                         &kp HOME &kp LC(END)      &kp LC(HOME) &kp END &none &none
                        &none &none &none &none &none &none &none     &none &none &none &none &none &none    &delete_line_win &none        &none   &none &none
                        &none &none &none &none &none       &kp LSHFT &none &none &none &none &none          &none            &none        &none   &none &none
            >;
        };

        
        layer_LineMac {
            bindings = <
                        &none &none &none &none &none                                                            &none        &none      &none         &none &none
                        &none &none &none &none &none &none                                         &none        &none        &none      &none         &none &none
                        &none &none &none &none &none &none                                         &none        &none        &none      &none         &none &none
                        &none &none &none &none &none &none                                         &kp LG(LEFT) &kp LG(DOWN) &kp LG(UP) &kp LG(RIGHT) &none &none
                        &none &none &none &none &none &none &none     &none &none &none &none &none &none        &kp LG(BSPC) &none      &none         &none &none
                        &none &none &none &none &none       &kp LSHFT &none &none &none &none &none              &none        &none      &none         &none &none
            >;
        };

        
        layer_TabpageWin {
            bindings = <
                        &none &none &none &none &none                                                         &none             &none             &none         &none &none
                        &none &none &none &none &none &none                                     &none         &none             &none             &none         &none &none
                        &none &none &none &none &none &none                                     &none         &none             &none             &none         &none &none
                        &none &none &none &none &none &none                                     &kp LC(PG_UP) &kp LC(LG(PG_DN)) &kp LC(LG(PG_UP)) &kp LC(PG_DN) &none &none
                        &none &none &none &none &none &none &none &none &none &none &none &none &none         &none             &none             &none         &none &none
                        &none &none &none &none &none       &none &none &none &none &none &none               &none             &none             &none         &none &none
            >;
        };

        
        layer_TabpageMac {
            bindings = <
                        &none &none &none &none &none                                                         &none             &none             &none         &none &none
                        &none &none &none &none &none &none                                     &none         &none             &none             &none         &none &none
                        &none &none &none &none &none &none                                     &none         &none             &none             &none         &none &none
                        &none &none &none &none &none &none                                     &kp LC(PG_UP) &kp LC(LG(PG_DN)) &kp LC(LG(PG_UP)) &kp LC(PG_DN) &none &none
                        &none &none &none &none &none &none &none &none &none &none &none &none &none         &none             &none             &none         &none &none
                        &none &none &none &none &none       &none &none &none &none &none &none               &none             &none             &none         &none &none
            >;
        };

        
        layer_BrowserWin {
            bindings = <
                        &none &none &none &none &none                                                         &none        &none         &none         &none &none
                        &none &none &none &none &none &none                                     &none         &none        &none         &none         &none &none
                        &none &none &none &none &none &none                                     &none         &none        &none         &none         &none &none
                        &none &none &none &none &none &none                                     &kp LC(PG_UP) &kp LA(LEFT) &kp LA(RIGHT) &kp LC(PG_DN) &none &none
                        &none &none &none &none &none &none &none &none &none &none &none &none &none         &none        &none         &none         &none &none
                        &none &none &none &none &none       &none &none &none &none &none &none               &none        &none         &none         &none &none
            >;
        };

        
        layer_BrowserMac {
            bindings = <
                        &none &none &none &none &none                                                         &none        &none         &none         &none &none
                        &none &none &none &none &none &none                                     &none         &none        &none         &none         &none &none
                        &none &none &none &none &none &none                                     &none         &none        &none         &none         &none &none
                        &none &none &none &none &none &none                                     &kp LC(PG_UP) &kp LG(LEFT) &kp LG(RIGHT) &kp LC(PG_DN) &none &none
                        &none &none &none &none &none &none &none &none &none &none &none &none &none         &none        &none         &none         &none &none
                        &none &none &none &none &none       &none &none &none &none &none &none               &none        &none         &none         &none &none
            >;
        };

        
        layer_Func {
            bindings = <
                        &none &none  &none  &none   &none                                                     &none   &none   &none   &none        &none
                        &none &none  &none  &none   &none   &none                                      &none  &none   &none   &none   &none        &none
                        &none &none  &none  &kp F11 &kp F12 &none                                      &kp F9 &kp F10 &kp F11 &kp F12 &none        &none
                        &none &kp F1 &kp F2 &kp F3  &kp F4  &kp F5                                     &kp F5 &kp F6  &kp F7  &kp F8  &kp C_VOL_DN &kp C_VOL_UP
                        &none &none  &none  &none   &none   &none  &none &none &none &none &none &none &kp F1 &kp F2  &kp F3  &kp F4  &none        &none
                        &none &none  &none  &none   &none          &none &none &none &none &none &none        &none   &none   &none   &none        &none
            >;
        }; 
        
        layer_WindowChangeWin {
            bindings = <
                        &none &none &none &none    &none                                                        &none    &none  &none     &none &none
                        &none &none &none &none    &none     &none                                     &none    &none    &none  &none     &none &none
                        &none &none &none &none    &none     &none                                     &none    &none    &none  &none     &none &none
                        &none &none &none &kp LEFT &kp RIGHT &none                                     &kp LEFT &kp DOWN &kp UP &kp RIGHT &none &none
                        &none &none &none &none    &none     &none &none &none &none &none &none &none &none    &none    &none  &none     &none &none
                        &none &none &none &none    &none           &none &none &none &none &none &none          &none    &none  &none     &none &none
            >;
        };
        
        layer_WindowChangeMac {
            bindings = <
                        &none &none &none &none    &none                                                        &none      &none      &none     &none &none
                        &none &none &none &none    &none     &none                                     &none    &none      &none      &none     &none &none
                        &none &none &none &kp DOWN &kp UP    &none                                     &none    &kp LC(N1) &kp LC(N2) &none     &none &none
                        &none &none &none &kp LEFT &kp RIGHT &none                                     &kp LEFT &kp DOWN   &kp UP     &kp RIGHT &none &none
                        &none &none &none &none    &none     &none &none &none &none &none &none &none &none    &none      &none      &none     &none &none
                        &none &none &none &none    &none           &none &none &none &none &none &none          &none      &none      &none     &none &none
            >;
        };

        layer_WindowChangeLinux {
            bindings = <
                        &none &none &none &none      &none                                                                       &none       &none         &none      &none      &none
                        &none &none &none &none      &none &none                                                       &none     &none       &none         &none      &none      &none
                        &none &none &none &none      &none &none                                                       &none     &kp LA(N1)  &kp LA(N2)    &kp LA(N3) &none      &none
                        &none &none &none &kp LSHIFT &none &none                                                       &kp LA(H) &kp LA(J)   &kp LA(K)     &kp LA(L)  &kp LA(N4) &none
                        &none &none &none &none      &none &none &none &none &none &none &none           &kp LA(SPACE) &none     &kp LA(DOT) &kp LA(COMMA) &kp LA(P)  &none      &none
                        &none &none &none &none      &none       &none &none &none &none &kp LA(LS(RET)) &kp LA(RET)             &none       &none         &none      &none      &none
            >;
        };
        
        layer_WindowMoveWin {
            bindings = <
                        &none &none &none &none &none                                                             &none         &none         &none         &none &none
                        &none &none &none &none &none      &none                                     &none        &none         &none         &none         &none &none
                        &none &none &none &none &none      &none                                     &none        &none         &none         &none         &none &none
                        &none &none &none &none &kp LG(UP) &none                                     &kp LG(LEFT) &kp LG(PG_DN) &kp LG(PG_UP) &kp LG(RIGHT) &none &none
                        &none &none &none &none &none      &none &none &none &none &none &none &none &none        &none         &none         &none         &none &none
                        &none &none &none &none &none            &none &none &none &none &none &none              &none         &none         &none         &none &none
            >;
        };

        
        layer_WindowMoveMac {
            bindings = <
                        &none &none &none &none &none                                                                    &none                 &none                   &none             &none &none
                        &none &none &none &none &none         &none                                     &none            &none                 &none                   &none             &none &none
                        &none &none &none &none &none         &none                                     &none            &kp LA(LG(LS(COMMA))) &kp LA(LG(LS(DOT)))     &none             &none &none
                        &none &none &none &none &kp LA(LG(F)) &none                                     &kp LA(LG(LEFT)) &kp LS(LA(LG(DOWN)))  &kp LS(LA(LG(UP)))      &kp LA(LG(RIGHT)) &none &none
                        &none &none &none &none &none         &none &none &none &none &none &none &none &none            &kp LA(LG(RBKT))      &kp LA(LG(NON_US_HASH)) &none             &none &none
                        &none &none &none &none &none               &none &none &none &none &none &none                  &none                 &none                   &none             &none &none
            >;
        };
    };
};
